VERSION ""

NS_ :

BS_:

BU_: XXX

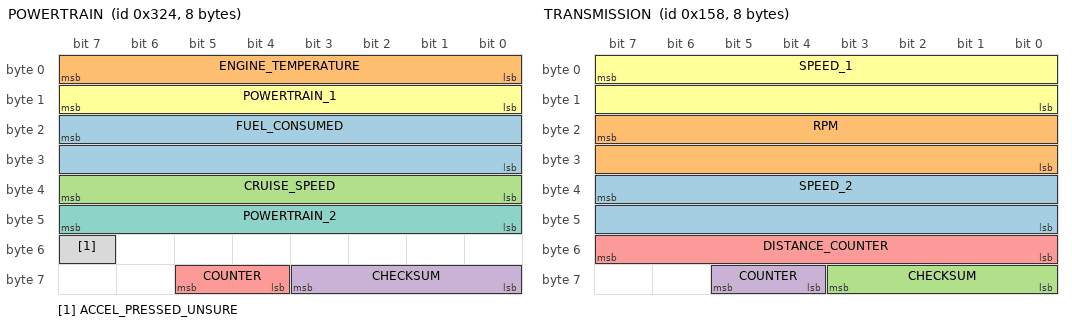
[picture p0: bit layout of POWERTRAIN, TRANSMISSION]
BO_ 804 POWERTRAIN: 8 XXX
 SG_ FUEL_CONSUMED : 23|16@0+ (1,0) [0|65535] "" XXX
 SG_ ENGINE_TEMPERATURE : 7|8@0+ (1,0) [0|255] "Degrees Celsius" XXX
 SG_ CRUISE_SPEED : 39|8@0+ (1,0) [0|255] "km/h" XXX
 SG_ CHECKSUM : 56|4@1+ (1,0) [0|15] "" XXX
 SG_ COUNTER : 61|2@0+ (1,0) [0|3] "" XXX
 SG_ POWERTRAIN_1 : 8|8@1+ (1,0) [0|255] "" XXX
 SG_ POWERTRAIN_2 : 47|8@0- (1,0) [0|255] "" XXX
 SG_ ACCEL_PRESSED_UNSURE : 55|1@0+ (1,0) [0|255] "" XXX

BO_ 660 LIGHTS: 8 XXX
 SG_ LEFT_TURN_SIGNAL : 5|1@0+ (1,0) [0|1] "" XXX
 SG_ RIGHT_TURN_SIGNAL : 6|1@0+ (1,0) [0|1] "" XXX

BO_ 344 TRANSMISSION: 8 XXX
 SG_ SPEED_2 : 39|16@0+ (0.01,0) [0|65535] "km/h" XXX
 SG_ RPM : 23|16@0+ (1,0) [0|65535] "" XXX
 SG_ CHECKSUM : 56|4@1+ (1,0) [0|15] "" XXX
 SG_ COUNTER : 61|2@0+ (1,0) [0|3] "" XXX
 SG_ DISTANCE_COUNTER : 55|8@0+ (1,0) [0|255] "" XXX
 SG_ SPEED_1 : 7|16@0+ (0.01,0) [0|65535] "km/h" XXX

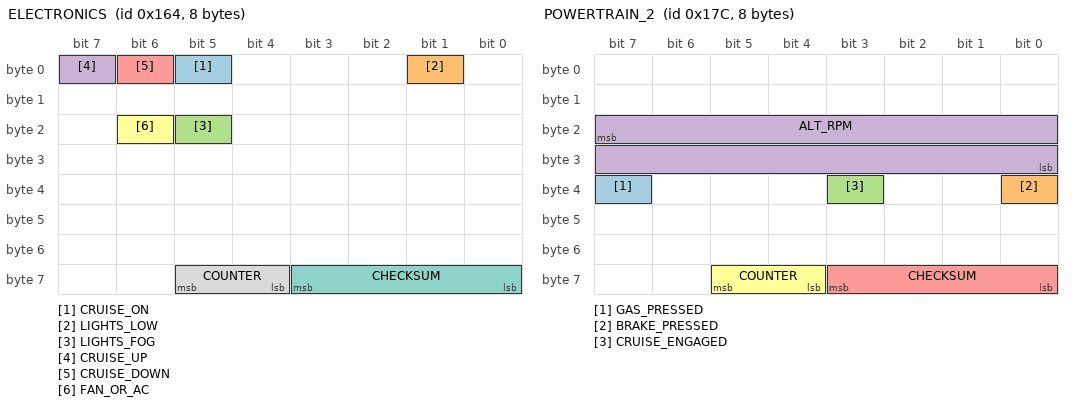
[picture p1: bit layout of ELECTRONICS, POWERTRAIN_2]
BO_ 356 ELECTRONICS: 8 XXX
 SG_ CRUISE_ON : 5|1@0+ (1,0) [0|1] "" XXX
 SG_ LIGHTS_LOW : 1|1@0+ (1,0) [0|1] "" XXX
 SG_ LIGHTS_FOG : 21|1@0+ (1,0) [0|1] "" XXX
 SG_ CRUISE_UP : 7|1@0+ (1,0) [0|1] "" XXX
 SG_ CRUISE_DOWN : 6|1@0+ (1,0) [0|1] "" XXX
 SG_ FAN_OR_AC : 22|1@0+ (1,0) [0|1] "" XXX
 SG_ CHECKSUM : 56|4@1+ (1,0) [0|15] "" XXX
 SG_ COUNTER : 61|2@0+ (1,0) [0|3] "" XXX

BO_ 380 POWERTRAIN_2: 8 XXX
 SG_ GAS_PRESSED : 39|1@0+ (1,0) [0|1] "" XXX
 SG_ BRAKE_PRESSED : 32|1@0+ (1,0) [0|1] "" XXX
 SG_ CRUISE_ENGAGED : 35|1@0+ (1,0) [0|1] "" XXX
 SG_ ALT_RPM : 23|16@0+ (1,0) [0|65535] "" XXX
 SG_ CHECKSUM : 56|4@1+ (1,0) [0|15] "" XXX
 SG_ COUNTER : 61|2@0+ (1,0) [0|3] "" XXX

BO_ 392 NEW_MSG_1: 6 XXX
 SG_ COUNTER : 45|2@0+ (1,0) [0|3] "" XXX
 SG_ CHECKSUM : 40|4@1+ (1,0) [0|15] "" XXX

BO_ 229 NEW_MSG_2: 4 XXX
 SG_ CHECKSUM : 24|4@1+ (1,0) [0|15] "" XXX
 SG_ COUNTER : 29|2@0+ (1,0) [0|3] "" XXX

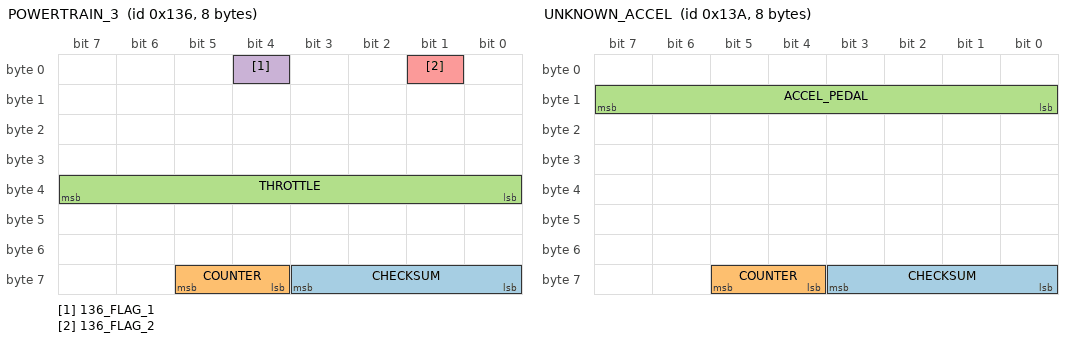
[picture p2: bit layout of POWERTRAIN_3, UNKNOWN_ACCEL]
BO_ 310 POWERTRAIN_3: 8 XXX
 SG_ CHECKSUM : 56|4@1+ (1,0) [0|15] "" XXX
 SG_ COUNTER : 61|2@0+ (1,0) [0|3] "" XXX
 SG_ THROTTLE : 32|8@1+ (1,0) [0|255] "" XXX
 SG_ 136_FLAG_1 : 4|1@0+ (1,0) [0|1] "" XXX
 SG_ 136_FLAG_2 : 1|1@0+ (1,0) [0|1] "" XXX

BO_ 314 UNKNOWN_ACCEL: 8 XXX
 SG_ CHECKSUM : 56|4@1+ (1,0) [0|15] "" XXX
 SG_ COUNTER : 61|2@0+ (1,0) [0|3] "" XXX
 SG_ ACCEL_PEDAL : 8|8@1+ (1,0) [0|255] "" XXX

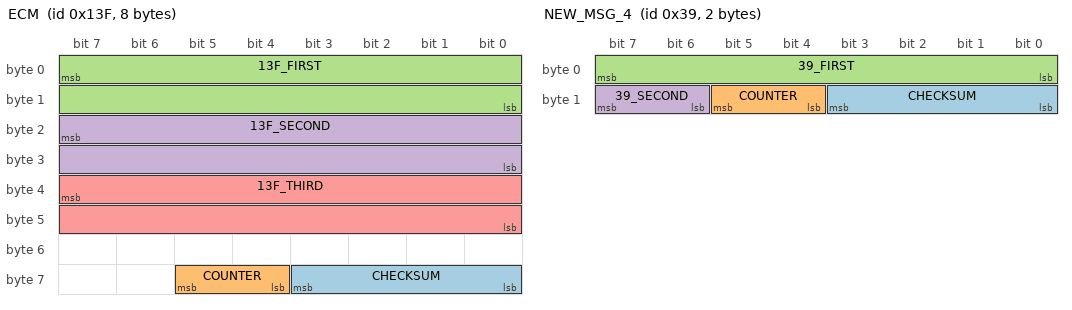
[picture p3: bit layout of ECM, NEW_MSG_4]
BO_ 319 ECM: 8 XXX
 SG_ CHECKSUM : 56|4@1+ (1,0) [0|15] "" XXX
 SG_ COUNTER : 61|2@0+ (1,0) [0|3] "" XXX
 SG_ 13F_FIRST : 7|16@0- (1,0) [0|65535] "" XXX
 SG_ 13F_SECOND : 23|16@0- (1,0) [0|65535] "" XXX
 SG_ 13F_THIRD : 39|16@0- (1,0) [0|65535] "" XXX

BO_ 149 NEW_MSG_3: 8 XXX
 SG_ CHECKSUM : 56|4@1+ (1,0) [0|15] "" XXX
 SG_ COUNTER : 61|2@0+ (1,0) [0|3] "" XXX

BO_ 57 NEW_MSG_4: 2 XXX
 SG_ CHECKSUM : 8|4@1+ (1,0) [0|15] "" XXX
 SG_ COUNTER : 13|2@0+ (1,0) [0|3] "" XXX
 SG_ 39_FIRST : 0|8@1+ (1,0) [0|255] "" XXX
 SG_ 39_SECOND : 15|2@0+ (1,0) [0|3] "" XXX

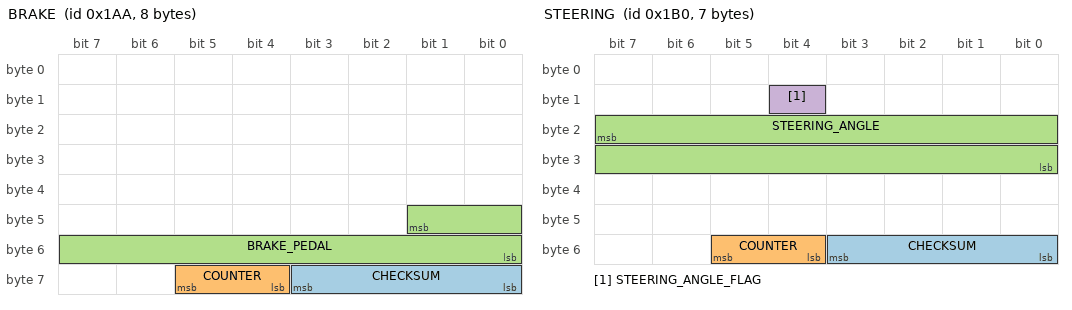
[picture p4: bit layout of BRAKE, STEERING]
BO_ 426 BRAKE: 8 XXX
 SG_ CHECKSUM : 56|4@1+ (1,0) [0|15] "" XXX
 SG_ COUNTER : 61|2@0+ (1,0) [0|3] "" XXX
 SG_ BRAKE_PEDAL : 41|10@0+ (0.01,0) [0|4095] "" XXX

BO_ 432 STEERING: 7 XXX
 SG_ CHECKSUM : 48|4@1+ (1,0) [0|15] "" XXX
 SG_ COUNTER : 53|2@0+ (1,0) [0|3] "" XXX
 SG_ STEERING_ANGLE : 23|16@0- (1,0) [0|65535] "" XXX
 SG_ STEERING_ANGLE_FLAG : 12|1@0+ (1,0) [0|65535] "" XXX

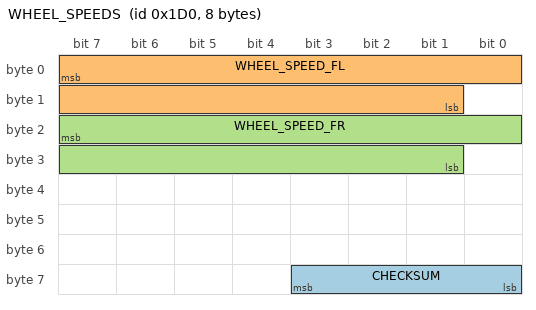
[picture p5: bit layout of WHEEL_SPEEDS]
BO_ 464 WHEEL_SPEEDS: 8 XXX
 SG_ CHECKSUM : 56|4@1+ (1,0) [0|15] "" XXX
 SG_ WHEEL_SPEED_FL : 7|15@0- (0.002759506,0) [0|32767] "" XXX
 SG_ WHEEL_SPEED_FR : 23|15@0- (0.002759506,0) [0|16383] "" XXX

CM_ SG_ 319 13F_THIRD "Always increments of 10";
CM_ SG_ 426 BRAKE_PEDAL "0x069 minimum, 0x2FF maximum";
CM_ SG_ 432 STEERING_ANGLE_FLAG "Seems to be triggered when STEERING_ANGLE is below 195";
